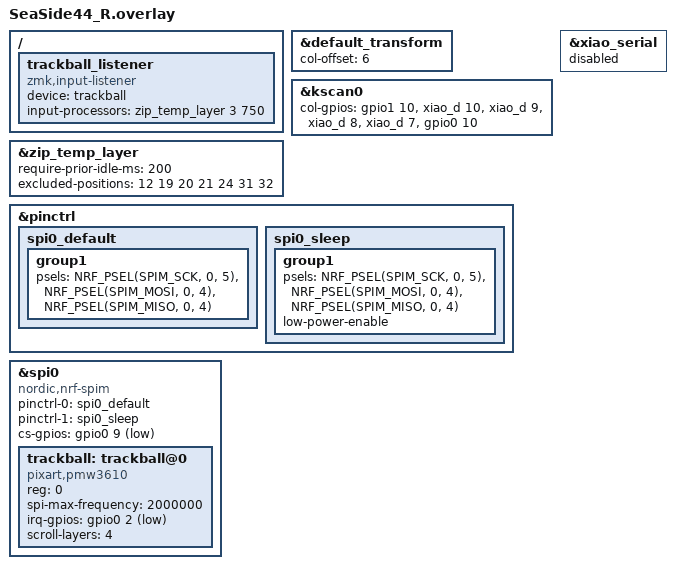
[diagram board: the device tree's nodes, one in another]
#include "SeaSide44.dtsi"
#include <input/processors.dtsi>

&default_transform {
    col-offset = <6>;
};

/* キーマトリクスの設定 */
// 上が外側、下が内側カラムcol番号と実際の配置が直感と逆になってる
&kscan0 {
        col-gpios
            = <&gpio1 10 GPIO_ACTIVE_HIGH>
            , <&xiao_d 10 GPIO_ACTIVE_HIGH>
            , <&xiao_d 9 GPIO_ACTIVE_HIGH>
            , <&xiao_d 8 GPIO_ACTIVE_HIGH>
            , <&xiao_d 7 GPIO_ACTIVE_HIGH>
            , <&gpio0 10 GPIO_ACTIVE_HIGH>
            ;
};

&zip_temp_layer {
    // キー入力中のオートマウスレイヤー誤爆防止。
    require-prior-idle-ms = <200>;

    // 当該以外のキーを押下すると AML が解除される。
    excluded-positions = <
        12 // Ctrl
        19 // J
        20 // K
        21 // L
        24 // Shift
        31 // M
        32 // <
    >;
};

/* Trackball のリスナー */
/ {
    trackball_listener {
        compatible = "zmk,input-listener";
        device = <&trackball>;

        // input processors による AML 有効化。
        input-processors = <&zip_temp_layer 3 750>;
    };
};

/* SPI 設定 */
&pinctrl {
    spi0_default: spi0_default {
        group1 {
            psels = <NRF_PSEL(SPIM_SCK, 0, 5)>,
                <NRF_PSEL(SPIM_MOSI, 0, 4)>,
                <NRF_PSEL(SPIM_MISO, 0, 4)>;
        };
    };

    spi0_sleep: spi0_sleep {
        group1 {
            psels = <NRF_PSEL(SPIM_SCK, 0, 5)>,
                <NRF_PSEL(SPIM_MOSI, 0, 4)>,
                <NRF_PSEL(SPIM_MISO, 0, 4)>;
            low-power-enable;
        };
    };
};

/* シリアルを無効化 */
&xiao_serial { status = "disabled"; };

/* SPI デバイス (トラックボール) */
&spi0 {
    status = "okay";
    compatible = "nordic,nrf-spim";
    pinctrl-0 = <&spi0_default>;
    pinctrl-1 = <&spi0_sleep>;
    pinctrl-names = "default", "sleep";
    cs-gpios = <&gpio0 9 GPIO_ACTIVE_LOW>;

    trackball: trackball@0 {
        status = "okay";
        compatible = "pixart,pmw3610";
        reg = <0>;
        spi-max-frequency = <2000000>;
        irq-gpios = <&gpio0 2 (GPIO_ACTIVE_LOW | GPIO_PULL_UP)>;
        // AML には input processors を使うので。
        // automouse-layer = <3>;
        scroll-layers = <4>;
    };
};

